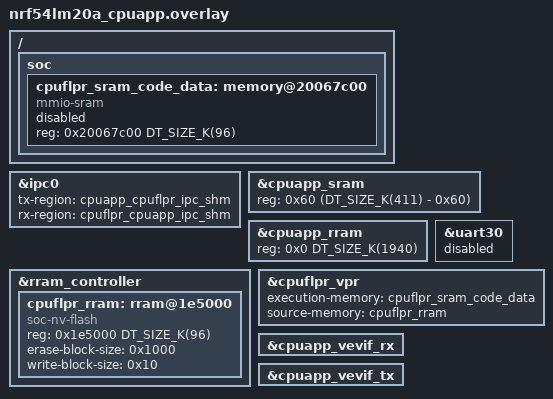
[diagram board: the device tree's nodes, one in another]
/*
 * Copyright (c) 2025 Nordic Semiconductor
 * SPDX-License-Identifier: Apache-2.0
 */

#include <nordic/nrf54lm20_a_b_ipc_shared_ram.dtsi>

/ {
	soc {
		cpuflpr_sram_code_data: memory@20067c00 {
			compatible = "mmio-sram";
			reg = <0x20067c00 DT_SIZE_K(96)>;
			ranges = <0x0 0x20067c00 0x18000>;
			status = "reserved";
			#address-cells = <1>;
			#size-cells = <1>;
		};
	};
};

&ipc0 {
	status = "okay";
	tx-region = <&cpuapp_cpuflpr_ipc_shm>;
	rx-region = <&cpuflpr_cpuapp_ipc_shm>;
};

&cpuapp_sram {
	reg = <0x60 (DT_SIZE_K(411) - 0x60)>;
};

&cpuapp_rram {
	reg = <0x0 DT_SIZE_K(1940)>;
	ranges = <0x0 0x0 DT_SIZE_K(1940)>;

	/delete-node/ partitions;
};

&rram_controller {
	cpuflpr_rram: rram@1e5000 {
		compatible = "soc-nv-flash";
		reg = <0x1e5000 DT_SIZE_K(96)>;
		ranges = <0x0 0x1e5000 DT_SIZE_K(96)>;
		erase-block-size = <0x1000>;
		write-block-size = <0x10>;
		#address-cells = <1>;
		#size-cells = <1>;
	};
};

&uart30 {
	status = "reserved";
};

&cpuflpr_vpr {
	execution-memory = <&cpuflpr_sram_code_data>;
	source-memory = <&cpuflpr_rram>;
};

&cpuapp_vevif_rx {
	status = "okay";
};

&cpuapp_vevif_tx {
	status = "okay";
};

#define WITH_FLPR_PARTITIONS
#include <vendor/nordic/nrf54lm20a_cpuapp_partition.dtsi>
